# allwinner_d1_unofficial register map
File version: 0.1
Registers are 32-bit, read-write, reset 0x0 unless marked. A register's access mark holds for its fields unless they carry their own. Offsets are from the block's base; [hi:lo] are bit positions.

## UART0 — Universal Asynchronous Receiver Transmitter
Base 0x02500000
Same registers: UART1 0x02500400, UART2 0x02500800, UART3 0x02500C00, UART4 0x02501000, UART5 0x02501400
0x00 RBR ro — UART Receive Buffer Register
  [7:0] rbr
0x00 THR wo — UART Transmit Holding Register
  [7:0] thr
0x00 DLL — UART Divisor Latch Low Register
  [7:0] dll
0x04 DLH — UART Divisor Latch High Register
  [7:0] dlh
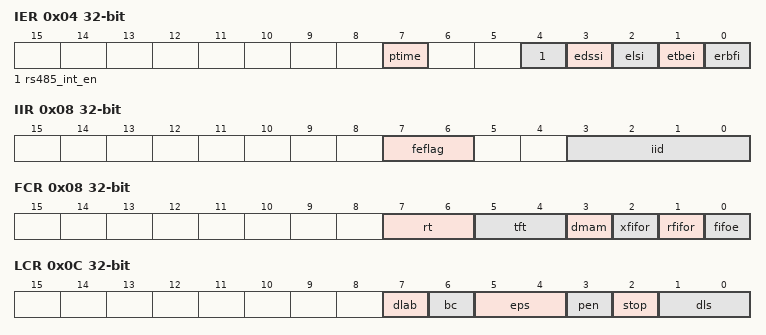
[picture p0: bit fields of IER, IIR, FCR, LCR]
0x04 IER — UART Interrupt Enable Register
  [all] fields
    0=disable; 1=enable
  [7] ptime — Programmable THRE Interrupt Mode Enable
  [4] rs485_int_en — RS485 Interrupt Enable
  [3] edssi — Enable Modem Status Interrupt
  [2] elsi — Enable Receiver Line Status Interrupt
  [1] etbei — Enable Transmit Holding Register Empty Interrupt
  [0] erbfi — Enable Received Data Available Interrupt
0x08 IIR ro — UART Interrupt Identity Register
  [7:6] feflag — FIFOs Enable Flag
    0=disable; 3=enable
  [3:0] iid — Interrupt ID
    0=modem_status; 1=no_interrupt_pending; 2=thr_empty; 3=rs485_interrupt; 4=received_data_available; 6=receiver_line_status; 7=busy_detect; 12=character_timeout
0x08 FCR wo — UART FIFO Control Register
  [7:6] rt
    0=one_character; 1=quarter_full; 2=half_full; 3=two_less_than_full
  [5:4] tft
    0=empty; 1=two_characters; 2=quarter_full; 3=half_full
  [3] dmam
    0=mode_0; 1=mode_1
  [2] xfifor
  [1] rfifor
  [0] fifoe
0x0C LCR — UART Line Control Register
  [7] dlab — Divisor Latch Access Bit
    0=rx_buffer; 1=divisor_latch
  [6] bc — Break Control Bit
  [5:4] eps — Even Parity Select
    0=odd; 1=even; 2=rs485_data; 3=rs485_addr
  [3] pen — Parity Enable
    0=disabled; 1=enabled
  [2] stop — Number of stop bits
    0=one (1 stop bit); 1=two (1.5 stop bits when DLS(LCR[1:0]) is zero, else 2 stop bits)
  [1:0] dls — Data Length Select
    0=five (5 bits); 1=six (6 bits); 2=seven (7 bits); 3=eight (8 bits)
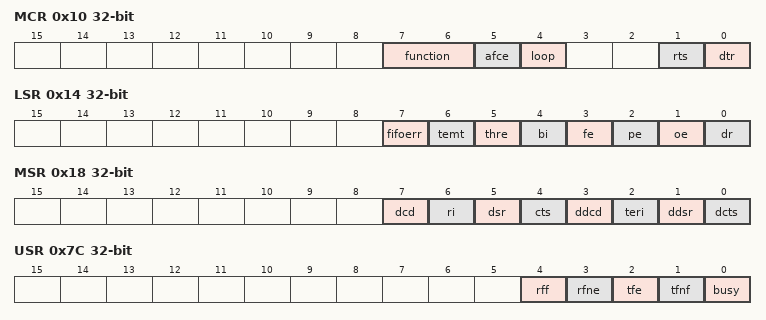
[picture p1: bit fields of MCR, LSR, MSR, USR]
0x10 MCR — UART Modem Control Register
  [7:6] function — UART Function: Select IrDA or RS485
    0=UART; 1=IrDA_SIR; 2=RS485
  [5] afce — Auto Flow Control Enable
    0=disabled; 1=enabled
  [4] loop — Loop Back Mode
    0=normal; 1=loop_back
  [1] rts — Request to Send
    0=deasserted; 1=asserted
  [0] dtr — Data Terminal Ready
    0=deasserted; 1=asserted
0x14 LSR ro — UART Line Status Register
  [7] fifoerr — RX Data Error in FIFO
    1=error
  [6] temt — Transmitter Empty
    1=empty
  [5] thre — TX Holding Register Empty
    1=empty
  [4] bi — Break Interrupt
  [3] fe — Framing Error
    1=error
  [2] pe — Parity Error
    1=error
  [1] oe — Overrun Error
    1=error
  [0] dr — Data Ready
    1=ready
0x18 MSR ro — UART Modem Status Register
  [7] dcd — Line State of Data Carrier Detect
    0=deasserted; 1=asserted
  [6] ri — Line State of Ring Indicator
    0=deasserted; 1=asserted
  [5] dsr — Line State of Data Set Ready
    0=deasserted; 1=asserted
  [4] cts — Line State of Clear To Send
    0=deasserted; 1=asserted
  [3] ddcd — Delta Data Carrier Detect
    0=no_change; 1=change
  [2] teri — Trailing Edge Ring Indicator
    0=no_change; 1=change
  [1] ddsr — Delta Data Set Ready
    0=no_change; 1=change
  [0] dcts — Delta Clear to Send
    0=no_change; 1=change
0x1C SCH — UART Scratch Register
  [7:0] scratch
0x7C USR ro — UART Status Register
  [4] rff — RX FIFO Full
    0=not_full; 1=full
  [3] rfne — RX FIFO Not Empty
    0=empty; 1=not_empty
  [2] tfe — TX FIFO Empty
    0=not_empty; 1=empty
  [1] tfnf — TX FIFO Not Full
    0=full; 1=not_full
  [0] busy — UART Busy Bit
    0=idle; 1=busy
0x80 TFL ro — UART Transmit FIFO Level Register
  [8:0] tfl — TX FIFO Level
0x84 RFL ro — UART Receive FIFO Level Register
  [8:0] rfl — RX FIFO Level
0x88 HSK — UART DMA Handshake Configuration Register
  [7:0] hsk — Handshake configuration
    165=wait_cycle; 229=handshake
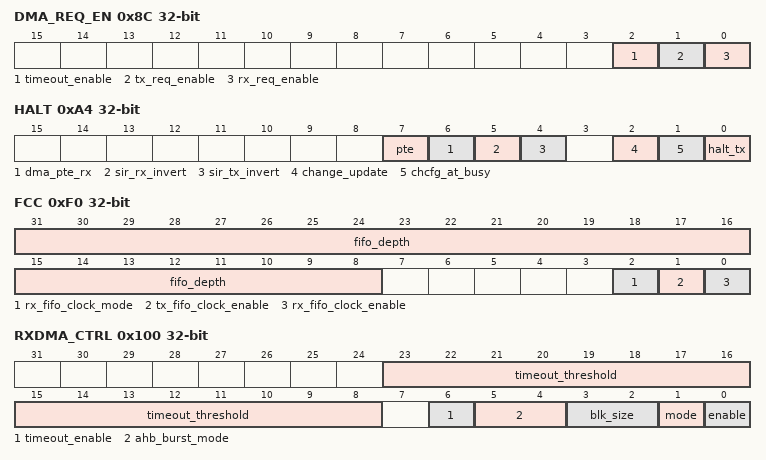
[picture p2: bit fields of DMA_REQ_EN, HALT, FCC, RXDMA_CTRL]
0x8C DMA_REQ_EN — UART DMA Request Enable Register
  [all] fields
    0=disable; 1=enable
  [2] timeout_enable — DMA Timeout Enable
  [1] tx_req_enable — DMA TX REQ Enable
  [0] rx_req_enable — DMA RX REQ Enable
0xA4 HALT — UART Halt TX Register
  [7] pte — The sending of TX_REQ
  [6] dma_pte_rx — The Transmission of RX_DRQ
  [5] sir_rx_invert — SIR RX Pulse Polarity Invert
    0=not_invert; 1=invert
  [4] sir_tx_invert — SIR TX Pulse Polarity Invert
    0=not_invert; 1=invert
  [2] change_update
    0=finished; 1=update_trigger
  [1] chcfg_at_busy
    0=disable; 1=enable
  [0] halt_tx
    0=disabled; 1=enabled
0xB0 DBG_DLL ro — UART Debug DLL Register
  [7:0] DBG_DLL
0xB4 DBG_DLH ro — UART Debug DLH Register
  [7:0] DBG_DLH
0xF0 FCC — UART FIFO Clock Control Register
  [31:8] fifo_depth ro
  [2] rx_fifo_clock_mode
    0=wr_apb (Sync mode, writing/reading clocks use apb clock); 1=w_apb_r_ahb (Sync mode, writing clock uses apb clock, reading clock uses ahb clock)
  [1] tx_fifo_clock_enable
    0=disable; 1=enable
  [0] rx_fifo_clock_enable
    0=disable; 1=enable
0x100 RXDMA_CTRL — UART RXDMA Control Register
  [23:8] timeout_threshold — RXDMA Timeout Threshold . Unit is 1 UART bit time
  [6] timeout_enable — RXDMA Timeout Enable
  [5:4] ahb_burst_mode — Set for AHB port burst supported
    0=SINGLE; 1=INCR4; 2=INCR8; 3=INCR16
  [3:2] blk_size
    0=B8; 1=B16; 2=B32; 3=B64
  [1] mode
    0=Continous; 1=Limited
  [0] enable
    0=Disable; 1=Enable
0x104 RXDMA_STR — UART RXDMA Start Register
  [0] start
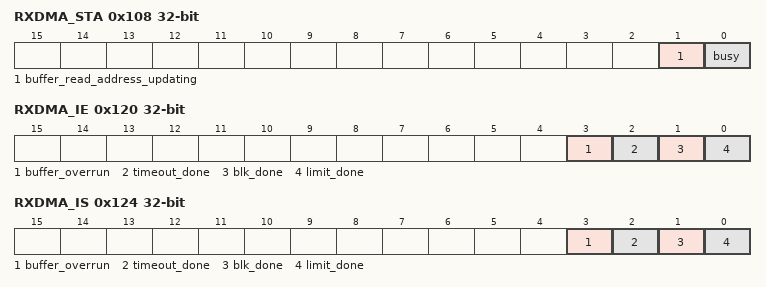
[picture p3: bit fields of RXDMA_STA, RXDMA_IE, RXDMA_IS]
0x108 RXDMA_STA — UART RXDMA Status Register
  [1] buffer_read_address_updating
    0=ready; 1=busy
  [0] busy
    0=idle; 1=busy
0x10C RXDMA_LMT — UART RXDMA Limit Register
  [15:0] limit_size
0x110 RXDMA_SADDRL — UART RXDMA Buffer Start Address Low Register
0x114 RXDMA_SADDRH — UART RXDMA Buffer Start Address High Register
  [1:0] saddr — RXDMA Buffer Start Address [33:32]
0x118 RXDMA_BL — UART RXDMA Buffer Length Register
  [15:0] buffer_length
0x120 RXDMA_IE — UART RXDMA Interrupt Enable Register
  [3] buffer_overrun, [2] timeout_done, [1] blk_done, [0] limit_done
0x124 RXDMA_IS — UART RXDMA Interrupt Status Register
  [3] buffer_overrun, [2] timeout_done, [1] blk_done, [0] limit_done
0x128 RXDMA_WADDRL ro — UART RXDMA Write Address Low Register
0x12C RXDMA_WADDRH ro — UART RXDMA Write Address High Register
  [1:0] waddr — RXDMA Current Write Address [33:32]
0x130 RXDMA_RADDRL — UART RXDMA Read Address Low Register
0x134 RXDMA_RADDRH — UART RXDMA Read Address High Register
  [1:0] raddr — RXDMA Current Read Address [33:32]
0x138 RXDMA_DCNT — UART RXDMA Data Count Register
  [15:0] data_count
